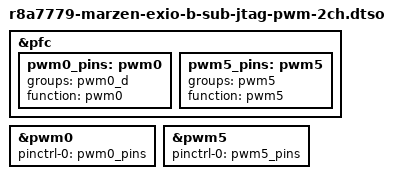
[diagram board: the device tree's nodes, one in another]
// SPDX-License-Identifier: GPL-2.0-only
//
// Device Tree Overlay for 2-channel PWM on r8a7779/marzen EXIO B or SUB_JTAG
//
// Copyright (C) 2023 Glider bv
//
// Pinout:
//   - PWM0 = EXIO B pin 81 or CN7 SUB_JTAG pin 2
//   - PWM5 = EXIO B pin 79 or CN7 SUB_JTAG pin 3
//   - GND  = EXIO B pin 73/85/90/93/98/104 or CN7 SUB_JTAG pin 10/12/13/14

/dts-v1/;
/plugin/;

&pfc {
	pwm0_pins: pwm0 {
		groups = "pwm0_d";
		function = "pwm0";
	};

	pwm5_pins: pwm5 {
		groups = "pwm5";
		function = "pwm5";
	};
};

&pwm0 {
	pinctrl-0 = <&pwm0_pins>;
	pinctrl-names = "default";

	status = "okay";
};

&pwm5 {
	pinctrl-0 = <&pwm5_pins>;
	pinctrl-names = "default";

	status = "okay";
};
